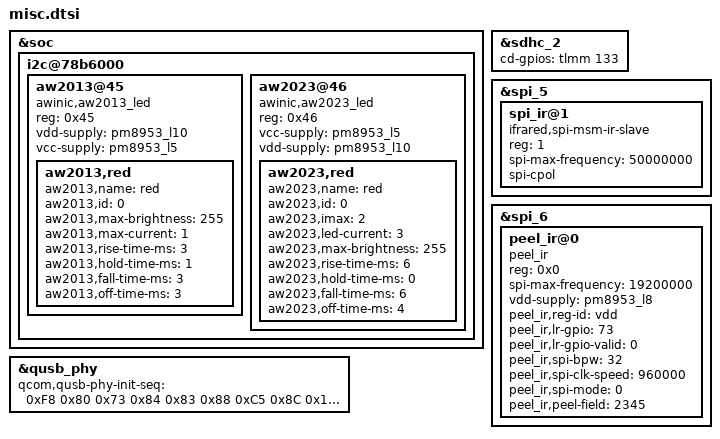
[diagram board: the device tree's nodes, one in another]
&soc {
	i2c@78b6000 { /* BLSP1 QUP3 */
		aw2013@45 {
			compatible = "awinic,aw2013_led";
			reg = <0x45>;
			vdd-supply = <&pm8953_l10>;
			vcc-supply = <&pm8953_l5>;

			aw2013,red {
				aw2013,name = "red";
				aw2013,id = <0>;
				aw2013,max-brightness = <255>;
				aw2013,max-current = <1>;
				aw2013,rise-time-ms = <3>;
				aw2013,hold-time-ms = <1>;
				aw2013,fall-time-ms = <3>;
				aw2013,off-time-ms = <3>;
			};
		};

		aw2023@46 {
			compatible = "awinic,aw2023_led";
			reg = <0x46>;
			vcc-supply = <&pm8953_l5>;
			vdd-supply = <&pm8953_l10>;

			aw2023,red {
				aw2023,name = "red";
				aw2023,id = <0>;
				aw2023,imax = <2>;
				aw2023,led-current = <3>;
				aw2023,max-brightness = <255>;
				aw2023,rise-time-ms = <6>;
				aw2023,hold-time-ms = <0>;
				aw2023,fall-time-ms = <6>;
				aw2023,off-time-ms = <4>;
			};
		};
	};
};

&sdhc_2 {
	cd-gpios = <&tlmm 133 0x0>;
};

&spi_5 {
	status = "ok";
	    spi_ir@1 {
	        compatible = "ifrared,spi-msm-ir-slave";
	        reg = <1>; /* Chip select 0 */
	        spi-max-frequency = <50000000>;
	        spi-cpol;
	        status = "ok";
	    };
};

&spi_6 {
	status = "ok";
	peel_ir@0 {
		compatible = "peel_ir";
		reg = <0x0>;
		spi-max-frequency = <19200000>;
		vdd-supply = <&pm8953_l8>; //vdd
		peel_ir,reg-id = "vdd";
		peel_ir,lr-gpio = <73>;
		peel_ir,lr-gpio-valid = <0>;
		peel_ir,spi-bpw = <32>;
		peel_ir,spi-clk-speed = <960000>;
		peel_ir,spi-mode = <0>;
		peel_ir,peel-field = <2345>;
		status = "ok";
	};
};

&qusb_phy {
		qcom,qusb-phy-init-seq = <0xF8 0x80
					0x73 0x84
					0x83 0x88
					0xC5 0x8C
					0x14 0x9C
					0x30 0x08
					0x79 0x0C
					0x21 0x10
					0x00 0x90
					0x9F 0x1C
					0x00 0x18>;
};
